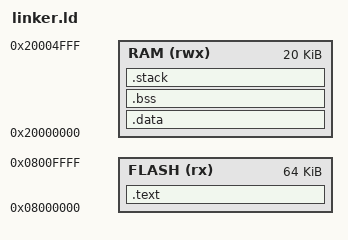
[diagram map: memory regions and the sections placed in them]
MEMORY
{
  FLASH (rx) : ORIGIN = 0x08000000, LENGTH = 64K
  RAM   (rwx): ORIGIN = 0x20000000, LENGTH = 20K
}

ENTRY(Reset_Handler)

SECTIONS
{
  .text :
  {
    KEEP(*(.isr_vector))
    *(.text*)
    *(.rodata*)
  } > FLASH

  .data : AT (ADDR(.text) + SIZEOF(.text))
  {
    _sdata = .;
    *(.data*)
    _edata = .;
  } > RAM

  .bss :
  {
    _sbss = .;
    *(.bss*)
    *(COMMON)
    _ebss = .;
  } > RAM

  .stack (NOLOAD) :
  {
    . = ALIGN(8);
    *(.stack)
  } > RAM

  _sidata = LOADADDR(.data);
  end = .;
}
